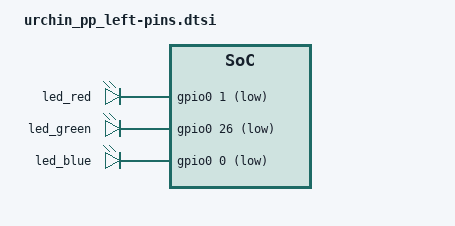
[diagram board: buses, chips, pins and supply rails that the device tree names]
/* Generated by scripts/firmware/gen_board.py from hardware/pinmap.json. Do not edit. */

&kscan0 {
    input-gpios
        = <&gpio0 17 (GPIO_ACTIVE_LOW | GPIO_PULL_UP)>  /* 0: r0c0 SW1, module pin 30 */
        , <&gpio0 22 (GPIO_ACTIVE_LOW | GPIO_PULL_UP)>  /* 1: r0c1 SW2, module pin 34 */
        , <&gpio1 0 (GPIO_ACTIVE_LOW | GPIO_PULL_UP)>  /* 2: r0c2 SW3, module pin 36 */
        , <&gpio1 2 (GPIO_ACTIVE_LOW | GPIO_PULL_UP)>  /* 3: r0c3 SW4, module pin 38 */
        , <&gpio1 4 (GPIO_ACTIVE_LOW | GPIO_PULL_UP)>  /* 4: r0c4 SW5, module pin 40 */
        , <&gpio0 7 (GPIO_ACTIVE_LOW | GPIO_PULL_UP)>  /* 5: r1c0 SW6, module pin 22 */
        , <&gpio0 15 (GPIO_ACTIVE_LOW | GPIO_PULL_UP)>  /* 6: r1c1 SW7, module pin 28 */
        , <&gpio0 13 (GPIO_ACTIVE_LOW | GPIO_PULL_UP)>  /* 7: r1c2 SW8, module pin 33 */
        , <&gpio0 20 (GPIO_ACTIVE_LOW | GPIO_PULL_UP)>  /* 8: r1c3 SW9, module pin 32 */
        , <&gpio0 24 (GPIO_ACTIVE_LOW | GPIO_PULL_UP)>  /* 9: r1c4 SW10, module pin 35 */
        , <&gpio0 8 (GPIO_ACTIVE_LOW | GPIO_PULL_UP)>  /* 10: r2c0 SW11, module pin 16 */
        , <&gpio0 4 (GPIO_ACTIVE_LOW | GPIO_PULL_UP)>  /* 11: r2c1 SW12, module pin 18 */
        , <&gpio0 12 (GPIO_ACTIVE_LOW | GPIO_PULL_UP)>  /* 12: r2c2 SW13, module pin 20 */
        , <&gpio1 9 (GPIO_ACTIVE_LOW | GPIO_PULL_UP)>  /* 13: r2c3 SW14, module pin 17 */
        , <&gpio0 5 (GPIO_ACTIVE_LOW | GPIO_PULL_UP)>  /* 14: r2c4 SW15, module pin 15 */
        , <&gpio0 6 (GPIO_ACTIVE_LOW | GPIO_PULL_UP)>  /* 15: t0 SW16, module pin 14 */
        , <&gpio0 30 (GPIO_ACTIVE_LOW | GPIO_PULL_UP)>  /* 16: t1 SW17, module pin 10 */
        ;
};

&led_red { gpios = <&gpio0 1 (GPIO_ACTIVE_LOW | GPIO_OPEN_DRAIN)>; };  /* status LED cathode, module pin 13 */
&led_green { gpios = <&gpio0 26 (GPIO_ACTIVE_LOW | GPIO_OPEN_DRAIN)>; };  /* status LED cathode, module pin 12 */
&led_blue { gpios = <&gpio0 0 (GPIO_ACTIVE_LOW | GPIO_OPEN_DRAIN)>; };  /* status LED cathode, module pin 11 */

&battery {
    power-good-gpios = <&gpio0 29 (GPIO_ACTIVE_LOW | GPIO_PULL_UP)>;  /* pgood_sense, module pin 8 */
    charging-gpios = <&gpio0 31 (GPIO_ACTIVE_LOW | GPIO_PULL_UP)>;  /* chg_sense, module pin 9 */
};
